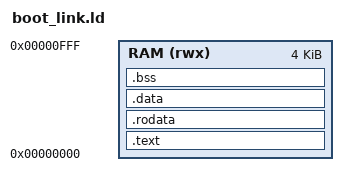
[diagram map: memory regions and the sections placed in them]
OUTPUT_ARCH(riscv)
ENTRY(_start)
MEMORY { RAM (rwx) : ORIGIN = 0, LENGTH = 4K }
SECTIONS {
    .text : { KEEP(*(.text.start)) *(.text .text.*) } > RAM
    .rodata : { *(.rodata .rodata.*) } > RAM
    .data : { *(.data .data.*) *(.sdata .sdata.*) } > RAM
    . = ALIGN(4);
    __bss_start = .;
    .bss (NOLOAD) : { *(.bss .bss.*) *(.sbss .sbss.*) *(COMMON) . = ALIGN(4); } > RAM
    __bss_end = .;
    __stack_top = ORIGIN(RAM) + LENGTH(RAM);
    ASSERT(__bss_end < __stack_top - 256, "Bootloader leaves insufficient stack space")
}
